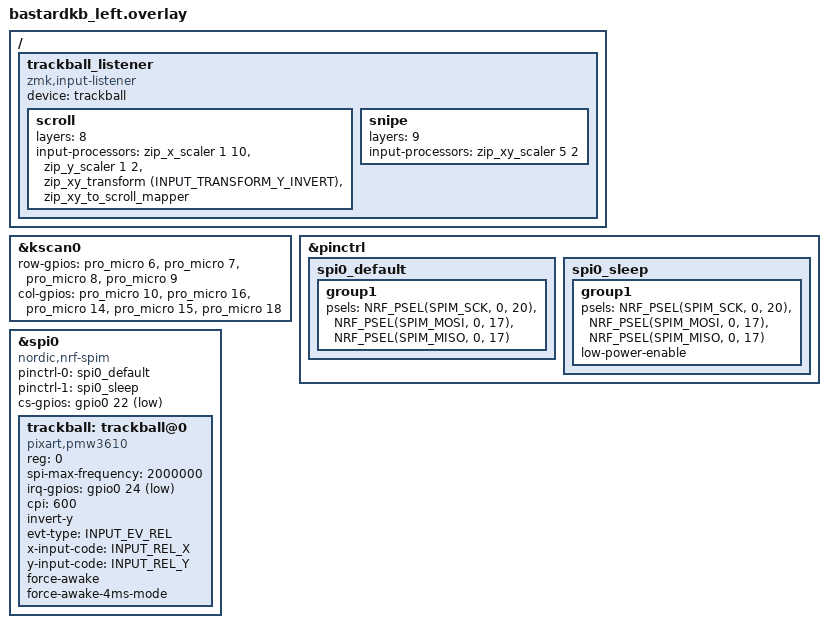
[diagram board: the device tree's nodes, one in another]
#include "bastardkb.dtsi" // Notice that the main dtsi files are included in the overlay.

&kscan0 {
    row-gpios
        = <&pro_micro 6 (GPIO_ACTIVE_HIGH | GPIO_PULL_DOWN)> // Row A from the schematic file
        , <&pro_micro 7 (GPIO_ACTIVE_HIGH | GPIO_PULL_DOWN)> // Row B from the schematic file
        , <&pro_micro 8 (GPIO_ACTIVE_HIGH | GPIO_PULL_DOWN)> // Row C from the schematic file
        , <&pro_micro 9 (GPIO_ACTIVE_HIGH | GPIO_PULL_DOWN)> // Row D from the schematic file
        ;
    col-gpios
        = <&pro_micro 10 GPIO_ACTIVE_HIGH> // col5 in the schematic
        , <&pro_micro 16 GPIO_ACTIVE_HIGH> // col4 in the schematic
        , <&pro_micro 14 GPIO_ACTIVE_HIGH> // col3 in the schematic
        , <&pro_micro 15 GPIO_ACTIVE_HIGH> // col2 in the schematic
        , <&pro_micro 18 GPIO_ACTIVE_HIGH> // col1 in the schematic
        ;
};

&pinctrl {
    spi0_default: spi0_default {
        group1 {
            psels = <NRF_PSEL(SPIM_SCK, 0, 20)>,
                <NRF_PSEL(SPIM_MOSI, 0, 17)>,
                <NRF_PSEL(SPIM_MISO, 0, 17)>;
        };
    };

    spi0_sleep: spi0_sleep {
        group1 {
            psels = <NRF_PSEL(SPIM_SCK, 0, 20)>,
                <NRF_PSEL(SPIM_MOSI, 0, 17)>,
                <NRF_PSEL(SPIM_MISO, 0, 17)>;
            low-power-enable;
        };
    };
};

#include <zephyr/dt-bindings/input/input-event-codes.h>

&spi0 {
    status = "okay";
    compatible = "nordic,nrf-spim";
    pinctrl-0 = <&spi0_default>;
    pinctrl-1 = <&spi0_sleep>;
    pinctrl-names = "default", "sleep";
    cs-gpios = <&gpio0 22 GPIO_ACTIVE_LOW>;

    trackball: trackball@0 {
        status = "okay";
        compatible = "pixart,pmw3610";
        reg = <0>;
        spi-max-frequency = <2000000>;
        irq-gpios = <&gpio0 24 (GPIO_ACTIVE_LOW | GPIO_PULL_UP)>;
        cpi = <600>;
        // swap-xy; /* optional */
        // invert-x; /* optional */
        invert-y; /* optional */
        evt-type = <INPUT_EV_REL>;
        x-input-code = <INPUT_REL_X>;
        y-input-code = <INPUT_REL_Y>;

        force-awake;
        /* keep the sensor awake while ZMK activity state is ACTIVE,
           fallback to normal downshift mode after ZMK goes into IDLE / SLEEP mode.
           thus, the sensor would be a `wakeup-source` */

        force-awake-4ms-mode;
        /* while force-awake is acitvated, enable this mode to force sampling per 
           4ms, where the default sampling rate is 8ms. */
        /* NOTE: apply this mode if you need 250Hz with direct USB connection. */
    };
};

/ {
    trackball_listener {
        compatible = "zmk,input-listener";
        device = <&trackball>;
        // input-processors = <&zip_temp_layer 7 800>; // Switch to auto-mouse temp layer, decrease sensitivity
        scroll {
            layers = <8>; // SCROLL
            input-processors = <&zip_x_scaler 1 10>, <&zip_y_scaler 1 2>, <&zip_xy_transform (INPUT_TRANSFORM_Y_INVERT)>, <&zip_xy_to_scroll_mapper>;
        };
        snipe {
            layers = <9>;
            input-processors = <&zip_xy_scaler 5 2>;
        };
    };

};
